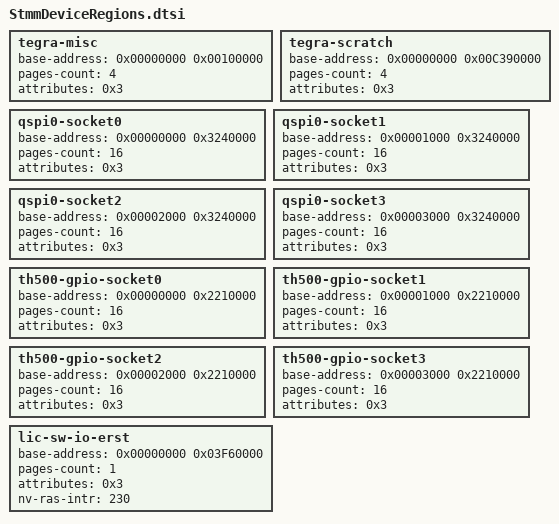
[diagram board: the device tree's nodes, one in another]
/*
 * SPDX-FileCopyrightText: Copyright (c) 2022 - 2025 NVIDIA CORPORATION & AFFILIATES. All rights reserved.
 *
 * SPDX-License-Identifier: BSD-3-Clause
 *
 * Device regions for the RASBaseServices driver
 *
 */

tegra-misc {
  base-address = < 0x00000000 0x00100000 >;
  pages-count  = < 4 >;
  attributes   = < 0x3 >;                   // read-write
};

tegra-scratch {
  base-address = < 0x00000000 0x00C390000 >;
  pages-count  = < 4 >;
  attributes   = < 0x3 >;                   // read-write
};

qspi0-socket0 {
  base-address = < 0x00000000 0x3240000 >;
  pages-count  = < 16 >;
  attributes   = < 0x3 >;                   // read-write
};

qspi0-socket1 {
  base-address = < 0x00001000 0x3240000 >;
  pages-count  = < 16 >;
  attributes   = < 0x3 >;                   // read-write
};

qspi0-socket2 {
  base-address = < 0x00002000 0x3240000 >;
  pages-count  = < 16 >;
  attributes   = < 0x3 >;                   // read-write
};

qspi0-socket3 {
  base-address = < 0x00003000 0x3240000 >;
  pages-count  = < 16 >;
  attributes   = < 0x3 >;                   // read-write
};

th500-gpio-socket0 {
  base-address = < 0x00000000 0x2210000 >;
  pages-count  = < 16 >;
  attributes   = < 0x3 >;                   // read-write
};

th500-gpio-socket1 {
  base-address = < 0x00001000 0x2210000 >;
  pages-count  = < 16 >;
  attributes   = < 0x3 >;                   // read-write
};

th500-gpio-socket2 {
  base-address = < 0x00002000 0x2210000 >;
  pages-count  = < 16 >;
  attributes   = < 0x3 >;                   // read-write
};

th500-gpio-socket3 {
  base-address = < 0x00003000 0x2210000 >;
  pages-count  = < 16 >;
  attributes   = < 0x3 >;                   // read-write
};

lic-sw-io-erst { /* TH500_SW_IO6_BASE */
	base-address = <0x00000000 0x03F60000>;
	pages-count = <1>;
	attributes = <0x3>; /* read-write */
	nv-ras-intr = <230>;
};
